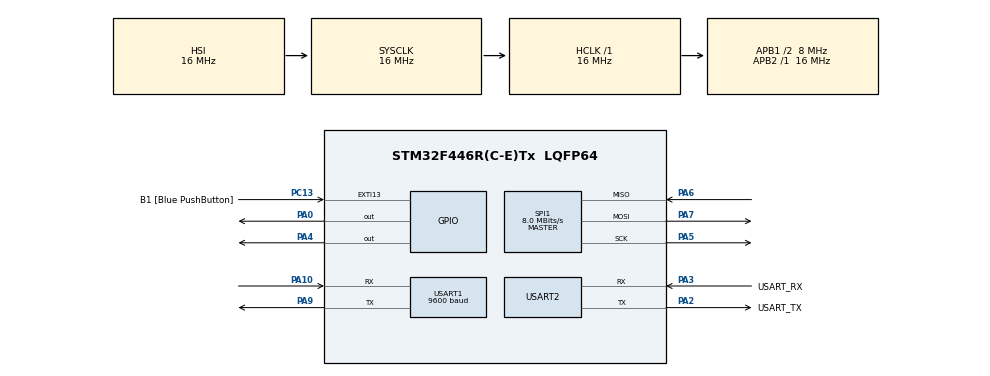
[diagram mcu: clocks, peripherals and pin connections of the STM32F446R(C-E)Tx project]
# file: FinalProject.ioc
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Mcu.Family=STM32F4
Mcu.Name=STM32F446R(C-E)Tx
Mcu.Package=LQFP64
NVIC.PriorityGroup=NVIC_PRIORITYGROUP_0
PA0-WKUP.Signal=GPIO_Output
PA10.Mode=Asynchronous
PA10.Signal=USART1_RX
PA13.GPIO_Label=TMS
PA13.Mode=Serial_Wire
PA13.Signal=SYS_JTMS-SWDIO
PA14.GPIO_Label=TCK
PA14.Mode=Serial_Wire
PA14.Signal=SYS_JTCK-SWCLK
PA2.GPIO_Label=USART_TX
PA2.Mode=Asynchronous
PA2.Signal=USART2_TX
PA3.GPIO_Label=USART_RX
PA3.Mode=Asynchronous
PA3.Signal=USART2_RX
PA4.Signal=GPIO_Output
PA5.Mode=Full_Duplex_Master
PA5.Signal=SPI1_SCK
PA6.Mode=Full_Duplex_Master
PA6.Signal=SPI1_MISO
PA7.Mode=Full_Duplex_Master
PA7.Signal=SPI1_MOSI
PA9.Mode=Asynchronous
PA9.Signal=USART1_TX
PB3.GPIO_Label=SWO
PB3.Signal=SYS_JTDO-SWO
PC13.GPIO_Label=B1 [Blue PushButton]
PC13.GPIO_ModeDefaultEXTI=GPIO_MODE_IT_FALLING
PC13.Signal=GPXTI13
PC14-OSC32_IN.Mode=LSE-External-Oscillator
PC14-OSC32_IN.Signal=RCC_OSC32_IN
PC15-OSC32_OUT.Mode=LSE-External-Oscillator
PC15-OSC32_OUT.Signal=RCC_OSC32_OUT
PH0-OSC_IN.Mode=HSE-External-Oscillator
PH0-OSC_IN.Signal=RCC_OSC_IN
PH1-OSC_OUT.Mode=HSE-External-Oscillator
PH1-OSC_OUT.Signal=RCC_OSC_OUT
ProjectManager.HeapSize=0x200
ProjectManager.StackSize=0x400
ProjectManager.TargetToolchain=SW4STM32
RCC.48MHZClocksFreq_Value=84000000
RCC.AHBFreq_Value=16000000
RCC.APB1CLKDivider=RCC_HCLK_DIV2
RCC.APB1Freq_Value=8000000
RCC.APB1TimFreq_Value=16000000
RCC.APB2Freq_Value=16000000
RCC.APB2TimFreq_Value=16000000
RCC.CortexFreq_Value=16000000
RCC.FLatency-AdvancedSettings=FLASH_LATENCY_0
RCC.HCLKFreq_Value=16000000
RCC.HSE_VALUE=8000000
RCC.HSI_VALUE=16000000
RCC.PLLM=8
RCC.PLLN=100
RCC.PLLP=RCC_PLLP_DIV4
RCC.SYSCLKFreq_VALUE=16000000
RCC.USBFreq_Value=100000000
RCC.VCOOutputFreq_Value=200000000
SPI1.BaudRatePrescaler=SPI_BAUDRATEPRESCALER_2
SPI1.CalculateBaudRate=8.0 MBits/s
SPI1.Direction=SPI_DIRECTION_2LINES
SPI1.Mode=SPI_MODE_MASTER
SPI1.VirtualType=VM_MASTER
USART1.BaudRate=9600
USART1.VirtualMode=VM_ASYNC
USART2.VirtualMode=VM_ASYNC
board=NUCLEO-F446RE

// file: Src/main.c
/* USER CODE BEGIN Header */
/**
  ******************************************************************************
  * @file           : main.c
  * @brief          : Main program body
  ******************************************************************************
  ** This notice applies to any and all portions of this file
  * that are not between comment pairs USER CODE BEGIN and
  * USER CODE END. Other portions of this file, whether
  * inserted by the user or by software development tools
  * are owned by their respective copyright owners.
  *
  * COPYRIGHT(c) 2019 STMicroelectronics
  *
  * Redistribution and use in source and binary forms, with or without modification,
  * are permitted provided that the following conditions are met:
  *   1. Redistributions of source code must retain the above copyright notice,
  *      this list of conditions and the following disclaimer.
  *   2. Redistributions in binary form must reproduce the above copyright notice,
  *      this list of conditions and the following disclaimer in the documentation
  *      and/or other materials provided with the distribution.
  *   3. Neither the name of STMicroelectronics nor the names of its contributors
  *      may be used to endorse or promote products derived from this software
  *      without specific prior written permission.
  *
  * THIS SOFTWARE IS PROVIDED BY THE COPYRIGHT HOLDERS AND CONTRIBUTORS "AS IS"
  * AND ANY EXPRESS OR IMPLIED WARRANTIES, INCLUDING, BUT NOT LIMITED TO, THE
  * IMPLIED WARRANTIES OF MERCHANTABILITY AND FITNESS FOR A PARTICULAR PURPOSE ARE
  * DISCLAIMED. IN NO EVENT SHALL THE COPYRIGHT HOLDER OR CONTRIBUTORS BE LIABLE
  * FOR ANY DIRECT, INDIRECT, INCIDENTAL, SPECIAL, EXEMPLARY, OR CONSEQUENTIAL
  * DAMAGES (INCLUDING, BUT NOT LIMITED TO, PROCUREMENT OF SUBSTITUTE GOODS OR
  * SERVICES; LOSS OF USE, DATA, OR PROFITS; OR BUSINESS INTERRUPTION) HOWEVER
  * CAUSED AND ON ANY THEORY OF LIABILITY, WHETHER IN CONTRACT, STRICT LIABILITY,
  * OR TORT (INCLUDING NEGLIGENCE OR OTHERWISE) ARISING IN ANY WAY OUT OF THE USE
  * OF THIS SOFTWARE, EVEN IF ADVISED OF THE POSSIBILITY OF SUCH DAMAGE.
  *
  ******************************************************************************
  */
/* USER CODE END Header */

#include "main.h"
#include "RC522.h"
#include "ds18b20_mflib.h"

/* USER CODE BEGIN PTD */
typedef struct _USER_MENU_ITEM
{
	char *Descr;
	void (*pfunc) ();
} USER_MENU_ITEM, *PUSER_MENU_ITEM;
/* USER CODE END PTD */

void PrintMenu (void);
void PRV_AcReady (void);
void HC06_ReadData(void);

static unsigned totalItems = 0;
static USER_MENU_ITEM UserMenu[] =
{
	{"\r 0- Print menu\n"						, PrintMenu},
	{"\r 1- RFID Read Version\n"				, MFRC522_ReadVersionRFID},
	{"\r 2- RFID Read card TYPE\n"				, MFRC522_ReadCardType},
	{"\r 3- RFID Read card UID(SerialNum)\n"	, MFRC522_ReadUIDCard},
	{"\r 4- RFID Read card Manufacturer Data\n"	, MFRC522_ReadCardManufData},
	{"\r 5- RFID Write DATA Block\n"			, MFRC522_WriteDataBlock},
	{"\r 6- RFID Read Data Block\n"				, MFRC522_ReadCardDataBlock},
	{"\r 7- RFID Write VALUE Block\n"			, MFRC522_WriteValueBlock},
	{"\r 8- RFID Read Value Block\n"			, MFRC522_ReadCardValueBlock},
	{"\r 9- RFID Read Block Access Bits\n"		, MFRC522_ReadSectorTrailerCardBlock},
	{"\r 10-RFID Increment Block\n"				, MFRC522_IncrementCardBlock},
	{"\r 11-RFID Decrement Block\n"				, MFRC522_DecrementCardBlock},
	{"\r 12-RFID Transfer Block\n"				, MFRC522_TransferCardBlock},
	{"\r 13-DS18B20 read Temperature\n"			, DS18B20_ReadTemperature},
	{"\r 14-Bluetooth HC-06 Receive Data\n"		, HC06_ReadData},
	{"\r 15-Read RFID and Set Air Conditioner\n", PRV_AcReady},
	{NULL, NULL}
};

SPI_HandleTypeDef hspi1;

UART_HandleTypeDef huart1;
UART_HandleTypeDef huart2;

void SystemClock_Config(void);
static void MX_GPIO_Init(void);
static void MX_USART2_UART_Init(void);
static void MX_SPI1_Init(void);
static void MX_USART1_UART_Init(void);

/* USER CODE BEGIN 0 */
uint32_t time_us;

uint8_t HC06Recive[10];
/* USER CODE END 0 */

int main(void)
{

  /* MCU Configuration--------------------------------------------------------*/

  /* Reset of all peripherals, Initializes the Flash interface and the Systick. */
  HAL_Init();

  /* Configure the system clock */
  SystemClock_Config();

  /* Initialize all configured peripherals */
  MX_GPIO_Init();
  MX_USART1_UART_Init();
  MX_USART2_UART_Init();
  MX_SPI1_Init();

  /* USER CODE BEGIN 2 */
  MFRC522_Init();
  /* USER CODE END 2 */

  /* Infinite loop */
  /* USER CODE BEGIN WHILE */
  int i=-1;
  PrintMenu();
  while (1)
  {
    /* USER CODE END WHILE */
	scanf("%d",&i);
	if (i>=0 && i<totalItems && UserMenu[i].pfunc)
	{
		UserMenu[i].pfunc();
	} else {
		PrintMenu();
	}
  }
}

void HC06_ReadData(void)
{
	while (1)
	{
		HAL_UART_Receive(&huart1,HC06Recive,6,100);
		if(HC06Recive[0]!='\0')
		{
			printf("%s\r\n",HC06Recive);
			HC06Recive[0]='\0';
			break;
			//
			//sendBluetoothString("alex1\r\n");
		}
	}
}

void SystemClock_Config(void)
{
  RCC_OscInitTypeDef RCC_OscInitStruct = {0};
  RCC_ClkInitTypeDef RCC_ClkInitStruct = {0};

  /**Configure the main internal regulator output voltage
  */
  __HAL_RCC_PWR_CLK_ENABLE();
  __HAL_PWR_VOLTAGESCALING_CONFIG(PWR_REGULATOR_VOLTAGE_SCALE3);
  /**Initializes the CPU, AHB and APB busses clocks
  */
  RCC_OscInitStruct.OscillatorType = RCC_OSCILLATORTYPE_HSI;
  RCC_OscInitStruct.HSIState = RCC_HSI_ON;
  RCC_OscInitStruct.HSICalibrationValue = RCC_HSICALIBRATION_DEFAULT;
  RCC_OscInitStruct.PLL.PLLState = RCC_PLL_NONE;
  if (HAL_RCC_OscConfig(&RCC_OscInitStruct) != HAL_OK)
  {
    Error_Handler();
  }
  /**Initializes the CPU, AHB and APB busses clocks
  */
  RCC_ClkInitStruct.ClockType = RCC_CLOCKTYPE_HCLK|RCC_CLOCKTYPE_SYSCLK
                              |RCC_CLOCKTYPE_PCLK1|RCC_CLOCKTYPE_PCLK2;
  RCC_ClkInitStruct.SYSCLKSource = RCC_SYSCLKSOURCE_HSI;
  RCC_ClkInitStruct.AHBCLKDivider = RCC_SYSCLK_DIV1;
  RCC_ClkInitStruct.APB1CLKDivider = RCC_HCLK_DIV2;
  RCC_ClkInitStruct.APB2CLKDivider = RCC_HCLK_DIV1;

  if (HAL_RCC_ClockConfig(&RCC_ClkInitStruct, FLASH_LATENCY_0) != HAL_OK)
  {
    Error_Handler();
  }
}

static void MX_SPI1_Init(void)
{

  /* SPI1 parameter configuration*/
  hspi1.Instance = SPI1;
  hspi1.Init.Mode = SPI_MODE_MASTER;
  hspi1.Init.Direction = SPI_DIRECTION_2LINES;
  hspi1.Init.DataSize = SPI_DATASIZE_8BIT;
  hspi1.Init.CLKPolarity = SPI_POLARITY_LOW;
  hspi1.Init.CLKPhase = SPI_PHASE_1EDGE;
  hspi1.Init.NSS = SPI_NSS_SOFT;
  hspi1.Init.BaudRatePrescaler = SPI_BAUDRATEPRESCALER_2;
  hspi1.Init.FirstBit = SPI_FIRSTBIT_MSB;
  hspi1.Init.TIMode = SPI_TIMODE_DISABLE;
  hspi1.Init.CRCCalculation = SPI_CRCCALCULATION_DISABLE;
  hspi1.Init.CRCPolynomial = 10;
  if (HAL_SPI_Init(&hspi1) != HAL_OK)
  {
    Error_Handler();
  }

}

static void MX_USART1_UART_Init(void)
{

  huart1.Instance = USART1;
  huart1.Init.BaudRate = 9600;
  huart1.Init.WordLength = UART_WORDLENGTH_8B;
  huart1.Init.StopBits = UART_STOPBITS_1;
  huart1.Init.Parity = UART_PARITY_NONE;
  huart1.Init.Mode = UART_MODE_TX_RX;
  huart1.Init.HwFlowCtl = UART_HWCONTROL_NONE;
  huart1.Init.OverSampling = UART_OVERSAMPLING_16;
  if (HAL_UART_Init(&huart1) != HAL_OK)
  {
    Error_Handler();
  }

}

static void MX_USART2_UART_Init(void)
{

  huart2.Instance = USART2;
  huart2.Init.BaudRate = 115200;
  huart2.Init.WordLength = UART_WORDLENGTH_8B;
  huart2.Init.StopBits = UART_STOPBITS_1;
  huart2.Init.Parity = UART_PARITY_NONE;
  huart2.Init.Mode = UART_MODE_TX_RX;
  huart2.Init.HwFlowCtl = UART_HWCONTROL_NONE;
  huart2.Init.OverSampling = UART_OVERSAMPLING_16;
  if (HAL_UART_Init(&huart2) != HAL_OK)
  {
    Error_Handler();
  }

}

static void MX_GPIO_Init(void)
{
  GPIO_InitTypeDef GPIO_InitStruct = {0};

  /* GPIO Ports Clock Enable */
  __HAL_RCC_GPIOC_CLK_ENABLE();
  __HAL_RCC_GPIOH_CLK_ENABLE();
  __HAL_RCC_GPIOA_CLK_ENABLE();
  __HAL_RCC_GPIOB_CLK_ENABLE();

  /*Configure GPIO pin Output Level */
  HAL_GPIO_WritePin(GPIOA, GPIO_PIN_0|GPIO_PIN_4, GPIO_PIN_RESET);

  /*Configure GPIO pin : B1_Pin */
  GPIO_InitStruct.Pin = B1_Pin;
  GPIO_InitStruct.Mode = GPIO_MODE_IT_FALLING;
  GPIO_InitStruct.Pull = GPIO_NOPULL;
  HAL_GPIO_Init(B1_GPIO_Port, &GPIO_InitStruct);

  /*Configure GPIO pins : PA0 PA4 */
  GPIO_InitStruct.Pin = GPIO_PIN_0|GPIO_PIN_4;
  GPIO_InitStruct.Mode = GPIO_MODE_OUTPUT_PP;
  GPIO_InitStruct.Pull = GPIO_NOPULL;
  GPIO_InitStruct.Speed = GPIO_SPEED_FREQ_LOW;
  HAL_GPIO_Init(GPIOA, &GPIO_InitStruct);

}

int _write(int file, char *data, int len)
{
	// arbitrary timeout 1000
	HAL_UART_Transmit(&huart2, (uint8_t*)data, len, 1000);
	return 0;
}

int _read (int file, char *ptr, int len)
{
	HAL_UART_Receive(&huart2,(uint8_t*)ptr++,1,0xffff);
	HAL_UART_Transmit(&huart2,(uint8_t *)(ptr-1),1,10);

	if (*(ptr-1)==0x0D){
		HAL_UART_Transmit(&huart2,(uint8_t *)"\n",1,10);
		*(ptr-1)='\n';
	}

	return 1;
}
void PrintMenu (void)
{
	PUSER_MENU_ITEM pMenuItem = UserMenu;
	while (pMenuItem->Descr != NULL) {
		printf("%s",pMenuItem->Descr);
		pMenuItem++;
		totalItems++;
	}
	printf("\r Enter Your choice: ");
   fflush(stdout);
}

void PRV_AcReady (void)
{
	char *UserName = MFRC522_GetDataBlock(1);
	printf("\r User on card is %s\n", UserName);

	int32_t tempOnCard = MFRC522_GetValueBlock(2);
	printf("\r User wants to be with %d Celsius degrees\n", (int)(tempOnCard));

	int32_t currentTemp = DS18B20_GetTemperature();
	printf("\r Current Temp is %d Celsius degrees\n", (int)(currentTemp));

	if(currentTemp != tempOnCard )
		printf("\r Start AC on %d Celsius degrees\n", (int)(tempOnCard));
	else
		printf("\r No need to operate the AC\n");
}
void Error_Handler(void)
{
}

/************************ (C) COPYRIGHT STMicroelectronics *****END OF FILE****/
